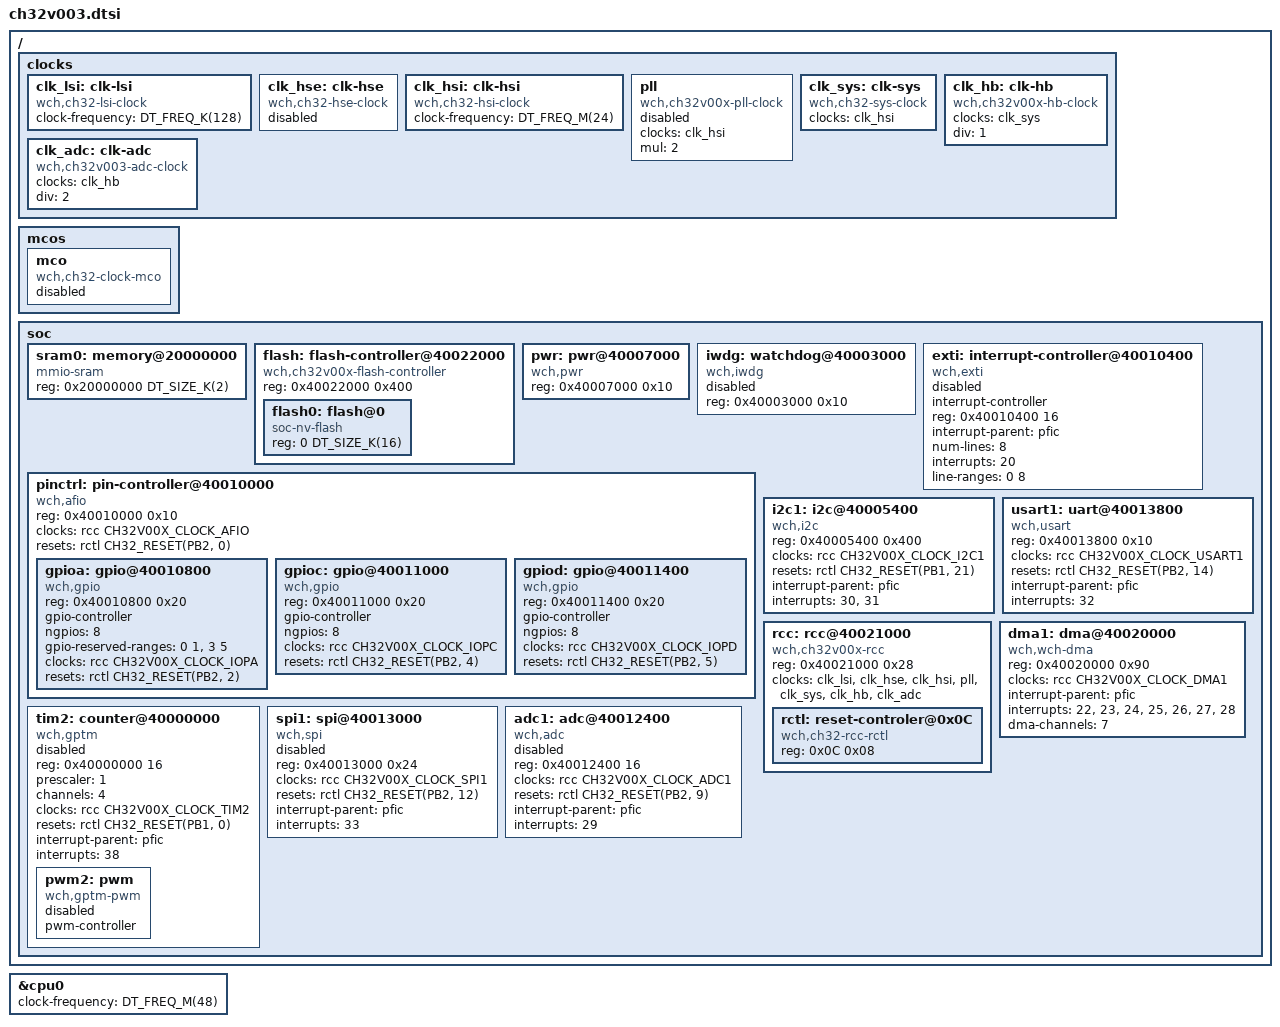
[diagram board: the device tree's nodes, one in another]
/*
 * Copyright (c) 2024 Michael Hope
 * Copyright (c) 2024 Paul Wedeck <paulwedeck@gmail.com>
 *
 * SPDX-License-Identifier: Apache-2.0
 */

#include <freq.h>
#include <mem.h>
#include <wch/qingke-v2a.dtsi>
#include <zephyr/dt-bindings/gpio/gpio.h>
#include <zephyr/dt-bindings/i2c/i2c.h>
#include <zephyr/dt-bindings/clock/ch32v00x-clocks.h>
#include <zephyr/dt-bindings/reset/ch32v00x-reset.h>
#include <zephyr/dt-bindings/dma/ch32v003-dma.h>

/ {
	clocks {
		clk_lsi: clk-lsi {
			#clock-cells = <0>;
			compatible = "wch,ch32-lsi-clock";
			clock-frequency = <DT_FREQ_K(128)>;
			status = "okay";
		};


		clk_hse: clk-hse {
			#clock-cells = <0>;
			compatible = "wch,ch32-hse-clock";
			status = "disabled";
		};

		clk_hsi: clk-hsi {
			#clock-cells = <0>;
			compatible = "wch,ch32-hsi-clock";
			clock-frequency = <DT_FREQ_M(24)>;
			status = "okay";
		};

		pll: pll {
			#clock-cells = <0>;
			compatible = "wch,ch32v00x-pll-clock";
			clocks = <&clk_hsi>;
			mul = <2>;
			status = "disabled";
		};

		clk_sys: clk-sys {
			#clock-cells = <0>;
			compatible = "wch,ch32-sys-clock";
			clocks = <&clk_hsi>;
		};

		clk_hb: clk-hb {
			#clock-cells = <0>;
			compatible = "wch,ch32v00x-hb-clock";
			clocks = <&clk_sys>;
			div = <1>;
		};

		clk_adc: clk-adc {
			#clock-cells = <0>;
			compatible = "wch,ch32v003-adc-clock";
			clocks = <&clk_hb>;
			div = <2>;
		};
	};

	mcos {
		mco: mco {
			compatible = "wch,ch32-clock-mco";
			status = "disabled";
		};
	};

	soc {
		sram0: memory@20000000 {
			compatible = "mmio-sram";
			reg = <0x20000000 DT_SIZE_K(2)>;
		};

		flash: flash-controller@40022000 {
			compatible = "wch,ch32v00x-flash-controller";
			reg = <0x40022000 0x400>;

			#address-cells = <1>;
			#size-cells = <1>;

			flash0: flash@0 {
				compatible = "soc-nv-flash";
				reg = <0 DT_SIZE_K(16)>;
			};
		};

		pwr: pwr@40007000 {
			compatible = "wch,pwr";
			reg = <0x40007000 0x10>;
		};

		iwdg: watchdog@40003000 {
			compatible = "wch,iwdg";
			reg = <0x40003000 0x10>;
			status = "disabled";
		};

		exti: interrupt-controller@40010400 {
			compatible = "wch,exti";
			interrupt-controller;
			#interrupt-cells = <1>;
			reg = <0x40010400 16>;
			interrupt-parent = <&pfic>;
			num-lines = <8>;
			interrupts = <20>;
			line-ranges = <0 8>;
			interrupt-names = "line0-7";
			status = "disabled";
		};

		pinctrl: pin-controller@40010000 {
			compatible = "wch,afio";
			reg = <0x40010000 0x10>;
			#address-cells = <1>;
			#size-cells = <1>;
			clocks = <&rcc CH32V00X_CLOCK_AFIO>;
			resets = <&rctl CH32_RESET(PB2, 0)>;
			status = "okay";

			gpioa: gpio@40010800 {
				compatible = "wch,gpio";
				reg = <0x40010800 0x20>;
				gpio-controller;
				#gpio-cells = <2>;
				ngpios = <8>;
				gpio-reserved-ranges = <0 1>, <3 5>;
				clocks = <&rcc CH32V00X_CLOCK_IOPA>;
				resets = <&rctl CH32_RESET(PB2, 2)>;
			};

			gpioc: gpio@40011000 {
				compatible = "wch,gpio";
				reg = <0x40011000 0x20>;
				gpio-controller;
				#gpio-cells = <2>;
				ngpios = <8>;
				clocks = <&rcc CH32V00X_CLOCK_IOPC>;
				resets = <&rctl CH32_RESET(PB2, 4)>;
			};

			gpiod: gpio@40011400 {
				compatible = "wch,gpio";
				reg = <0x40011400 0x20>;
				gpio-controller;
				#gpio-cells = <2>;
				ngpios = <8>;
				clocks = <&rcc CH32V00X_CLOCK_IOPD>;
				resets = <&rctl CH32_RESET(PB2, 5)>;
			};
		};

		i2c1: i2c@40005400 {
			compatible = "wch,i2c";
			#address-cells = <1>;
			#size-cells = <0>;
			reg = <0x40005400 0x400>;
			clocks = <&rcc CH32V00X_CLOCK_I2C1>;
			resets = <&rctl CH32_RESET(PB1, 21)>;
			interrupt-parent = <&pfic>;
			interrupts = <30>, <31>;
		};

		usart1: uart@40013800 {
			compatible = "wch,usart";
			reg = <0x40013800 0x10>;
			clocks = <&rcc CH32V00X_CLOCK_USART1>;
			resets = <&rctl CH32_RESET(PB2, 14)>;
			interrupt-parent = <&pfic>;
			interrupts = <32>;
		};

		rcc: rcc@40021000 {
			compatible = "wch,ch32v00x-rcc";
			reg = <0x40021000 0x28>;
			reg-names = "rcc";
			#address-cells = <1>;
			#size-cells = <1>;
			#clock-cells = <1>;
			clocks = <&clk_lsi>, <&clk_hse>, <&clk_hsi>, <&pll>,
			         <&clk_sys>, <&clk_hb>, <&clk_adc>;
			clock-names = "clk_lsi", "clk_hse", "clk_hsi", "pll",
			              "clk_sys", "clk_hb", "clk_adc";
			status = "okay";

			rctl: reset-controler@0x0C {
				compatible = "wch,ch32-rcc-rctl";
				#reset-cells = <1>;
				reg = <0x0C 0x08>;
				status = "okay";
			};
		};

		dma1: dma@40020000 {
			compatible = "wch,wch-dma";
			reg = <0x40020000 0x90>;
			clocks = <&rcc CH32V00X_CLOCK_DMA1>;
			#dma-cells = <1>;
			interrupt-parent = <&pfic>;
			interrupts = <22>, <23>, <24>, <25>, <26>, <27>, <28>;
			dma-channels = <7>;
		};

		tim2: counter@40000000 {
			compatible = "wch,gptm";
			reg = <0x40000000 16>;
			prescaler = <1>;
			channels = <4>;
			clocks = <&rcc CH32V00X_CLOCK_TIM2>;
			resets = <&rctl CH32_RESET(PB1, 0)>;
			interrupt-parent = <&pfic>;
			interrupts = <38>;
			interrupt-names = "global";
			status = "disabled";

			pwm2: pwm {
				compatible = "wch,gptm-pwm";
				pwm-controller;
				#pwm-cells = <3>;
				status = "disabled";
			};
		};

		spi1: spi@40013000 {
			compatible = "wch,spi";
			reg = <0x40013000 0x24>;
			clocks = <&rcc CH32V00X_CLOCK_SPI1>;
			resets = <&rctl CH32_RESET(PB2, 12)>;
			interrupt-parent = <&pfic>;
			interrupts = <33>;
			status = "disabled";
			#address-cells = <1>;
			#size-cells = <0>;
		};

		adc1: adc@40012400 {
			compatible = "wch,adc";
			reg = <0x40012400 16>;
			clocks = <&rcc CH32V00X_CLOCK_ADC1>;
			resets = <&rctl CH32_RESET(PB2, 9)>;
			interrupt-parent = <&pfic>;
			interrupts = <29>;
			#io-channel-cells = <1>;
			status = "disabled";
		};
	};
};

&cpu0 {
	clock-frequency = <DT_FREQ_M(48)>;
};
